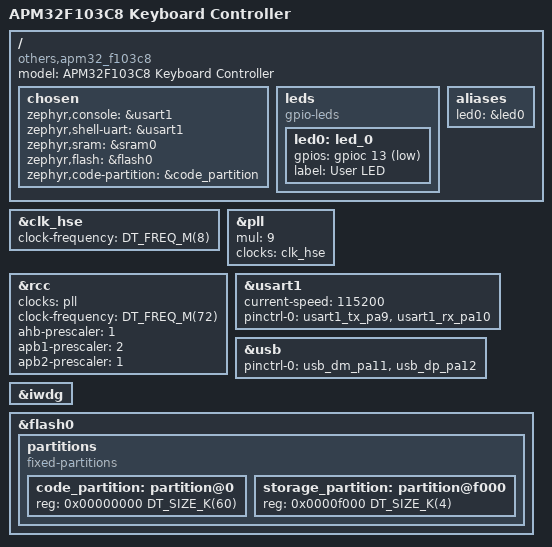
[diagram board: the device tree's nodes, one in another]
/*
 * Copyright (c) 2024 APM68 Keyboard
 *
 * SPDX-License-Identifier: MIT
 */

/dts-v1/;

#include <st/f1/stm32f103Xb.dtsi>
#include <st/f1/stm32f103c(8-b)tx-pinctrl.dtsi>

/ {
	model = "APM32F103C8 Keyboard Controller";
	compatible = "others,apm32_f103c8", "st,stm32f103xb";

	chosen {
		zephyr,console = &usart1;
		zephyr,shell-uart = &usart1;
		zephyr,sram = &sram0;
		zephyr,flash = &flash0;
		zephyr,code-partition = &code_partition;
	};

	leds {
		compatible = "gpio-leds";
		led0: led_0 {
			gpios = <&gpioc 13 GPIO_ACTIVE_LOW>;
			label = "User LED";
		};
	};

	aliases {
		led0 = &led0;
	};
};

&clk_hse {
	clock-frequency = <DT_FREQ_M(8)>;
	status = "okay";
};

&pll {
	mul = <9>;
	clocks = <&clk_hse>;
	status = "okay";
};

&rcc {
	clocks = <&pll>;
	clock-frequency = <DT_FREQ_M(72)>;
	ahb-prescaler = <1>;
	apb1-prescaler = <2>;
	apb2-prescaler = <1>;
};

&usart1 {
	status = "okay";
	current-speed = <115200>;
	pinctrl-0 = <&usart1_tx_pa9 &usart1_rx_pa10>;
	pinctrl-names = "default";
};

&usb {
	status = "okay";
	pinctrl-0 = <&usb_dm_pa11 &usb_dp_pa12>;
	pinctrl-names = "default";
};

&iwdg {
	status = "okay";
};

&flash0 {
	partitions {
		compatible = "fixed-partitions";
		#address-cells = <1>;
		#size-cells = <1>;

		/* Application code partition: 60KB */
		code_partition: partition@0 {
			reg = <0x00000000 DT_SIZE_K(60)>;
		};

		/* Storage partition for ZMK settings: 4KB */
		storage_partition: partition@f000 {
			reg = <0x0000f000 DT_SIZE_K(4)>;
		};
	};
};
